# STM32U575 register map
File version: 1.4
CPU: CM33 r0p1, little endian, MPU, FPU, 4 interrupt priority bits
Registers are 32-bit, read-write, reset 0x0 unless marked. A register's access mark holds for its fields unless they carry their own. Offsets are from the block's base; [hi:lo] are bit positions; lines under a group give offsets from that group; {n}, {i} and the like mark numbered series; <NAME> marks a mode.

## LPDMA1
Base 0x46025000
Same registers: SEC_LPDMA1 0x56025000
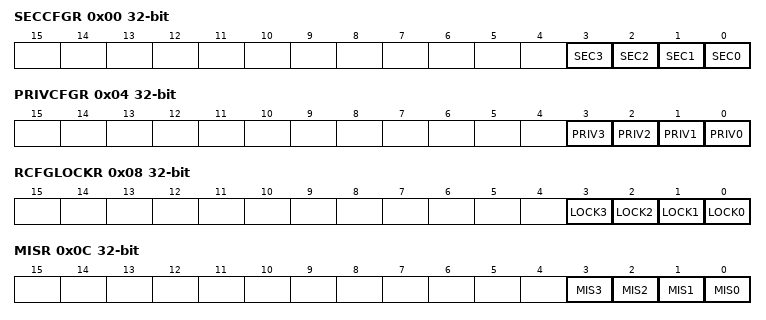
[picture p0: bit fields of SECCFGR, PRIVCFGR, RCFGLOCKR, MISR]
0x00 SECCFGR — LPDMA secure configuration register
  [n] SEC{n} (n=0..3) — SEC{n}
0x04 PRIVCFGR — LPDMA privileged configuration register
  [n] PRIV{n} (n=0..3) — PRIV{n}
0x08 RCFGLOCKR — LPDMA configuration lock register
  [n] LOCK{n} (n=0..3) — LOCK{n}
0x0C MISR ro — LPDMA non-secure masked interrupt status register
  [n] MIS{n} (n=0..3) — MIS{n}
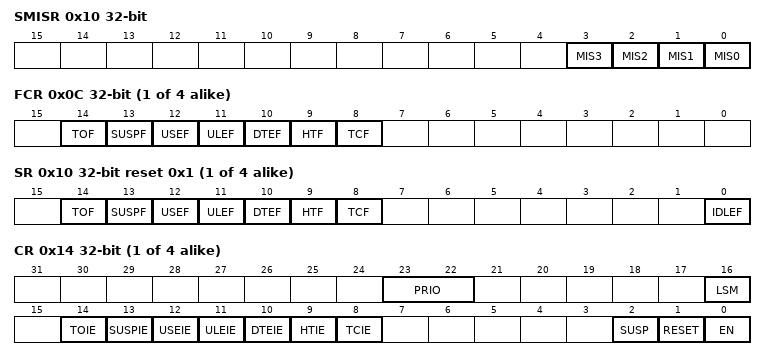
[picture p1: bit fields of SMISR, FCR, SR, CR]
0x10 SMISR ro — LPDMA secure masked interrupt status register
  [n] MIS{n} (n=0..3) — MIS{n}
{0x50+0x80*i} CH{i} (i=0..3) group — Cluster CH{i}, containing C?LBAR, C?FCR, C?SR, C?CR, C?TR1, C?TR2, C?BR1, C?SAR, C?DAR, C?LLR
  0x00 LBAR — LPDMA channel 0 linked-list base address register
    [31:16] LBA — linked-list base address of LPDMA channel x
  0x0C FCR wo — LPDMA channel 0 flag clear register
    [14] TOF — trigger overrun flag clear
    [13] SUSPF — completed suspension flag clear
    [12] USEF — user setting error flag clear
    [11] ULEF — update link transfer error flag clear
    [10] DTEF — data transfer error flag clear
    [9] HTF — half transfer flag clear
    [8] TCF — transfer complete flag clear
  0x10 SR ro reset 0x1 — LPDMA channel 0 status register
    [14] TOF — trigger overrun flag clear
    [13] SUSPF — completed suspension flag
    [12] USEF — user setting error flag
    [11] ULEF — update link transfer error flag
    [10] DTEF — data transfer error flag
    [9] HTF — half transfer flag An half transfer event is an half block transfer that occurs when half of the bytes of the source block size (rounded-up integer of LPDMA_CxBR1.BNDT[15:0] / 2) has been transferred to the destination.
    [8] TCF — transfer complete flag A transfer complete event is a block transfer complete or a LLI transfer complete including the upload of the next LLI if any, or the full linked-list completion, depending on the transfer complete event mode LPDMA_CxTR2.TCEM[1:0].
    [0] IDLEF — idle flag This idle flag is de-asserted by hardware when the channel is enabled (LPDMA_CxCR.EN = 1) with a valid channel configuration (no USEF to be immediately reported). This idle flag is asserted after hard reset or by hardware when the channel is back in idle state (in suspended or disabled state).
  0x14 CR access per field — LPDMA channel 0 control register
    [23:22] PRIO rw — priority level of the channel x LPDMA transfer versus others Note: This bit must be written when EN = 0. This bit is read-only when EN = 1.
    [16] LSM rw — Link step mode First the block transfer is executed as defined by the current internal register file until LPDMA_CxBR1.BNDT[15:0 ] =0). Secondly the next linked-list data structure is conditionally uploaded from memory as defined by LPDMA_CxLLR. Then channel execution is completed. Note: This bit must be written when EN=0. This bit is read-only when EN=1.
    [14] TOIE rw — trigger overrun interrupt enable
    [13] SUSPIE rw — completed suspension interrupt enable
    [12] USEIE rw — user setting error interrupt enable
    [11] ULEIE rw — update link transfer error interrupt enable
    [10] DTEIE rw — data transfer error interrupt enable
    [9] HTIE rw — half transfer complete interrupt enable
    [8] TCIE rw — transfer complete interrupt enable
    [2] SUSP rw — suspend Writing 1 into the field RESET (bit 1) causes the hardware to de-assert this bit, whatever is written into this bit 2. Else: Software must write 1 in order to suspend an active channel i.e. a channel with an on-going DMA transfer over its master ports. The software must write 0 in order to resume a suspended channel, following the programming sequence detailed in sequence.
    [1] RESET wo — reset This bit is write only. Writing 0 has no impact. Writing 1 implies the reset of the following: the channel internal state, SUSP and EN bits (whatever is written receptively in bit 2 and bit 0). The reset is effective when the channel is in steady state, meaning one of the following: - active channel in suspended state (LPDMA_CxSR.SUSPF = 1 and LPDMA_CxSR.IDLEF = LPDMA_CxCR.EN = 1) - channel in disabled state (LPDMA_CxSR.IDLEF = 1 and LPDMA_CxCR.EN = 0). After writing a RESET, to continue using this channel, the user must explicitly reconfigure the channel including the hardware-modified configuration registers (LPDMA_CxBR1, LPDMA_CxSAR and LPDMA_CxDAR) before enabling again the channel (see the programming sequence in ).
    [0] EN rw — enable Writing 1 into the field RESET (bit 1) causes the hardware to de-assert this bit, whatever is written into this bit 0. Else: this bit is de-asserted by hardware when there is a transfer error (master bus error or user setting error) or when there is a channel transfer complete (channel ready to be configured, e.g. if LSM=1 at the end of a single execution of the LLI). Else, this bit can be asserted by software. Writing 0 into this EN bit is ignored.
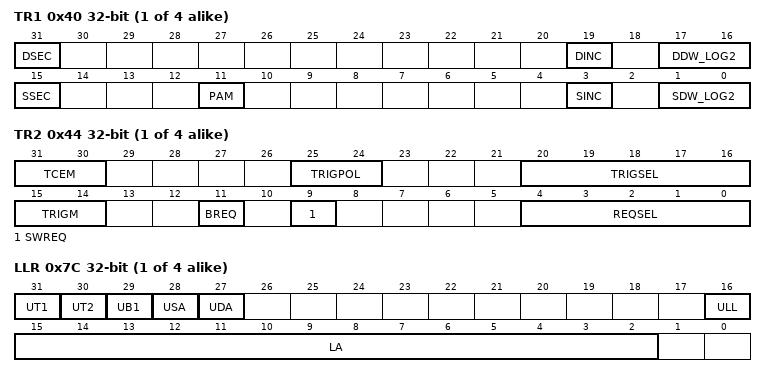
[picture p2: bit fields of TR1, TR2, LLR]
  0x40 TR1 — LPDMA channel 0 transfer register 1
    [31] DSEC — security attribute of the LPDMA transfer to the destination If LPDMA_SECCFGR.SECx = 1 and the access is secure: This is a secure register bit. This bit can only be read by a secure software. This bit must be written by a secure software when LPDMA_SECCFGR.SECx = 1. A secure write is ignored when LPDMA_SECCFGR.SECx = 0. When LPDMA_SECCFGR.SECx is de-asserted, this DSEC bit is also de-asserted by hardware (on a secure reconfiguration of the channel as non-secure), and the LPDMA transfer to the destination is non-secure.
    [19] DINC — destination incrementing single The destination address, pointed by LPDMA_CxDAR, is kept constant after a single transfer, or is incremented by the offset value corresponding to a contiguous data after a single transfer.
    [17:16] DDW_LOG2 — binary logarithm of the destination data width of a single in bytes Note: Setting a 8-byte data width causes a user setting error to be reported and none transfer is issued. A destination single transfer must have an aligned address with its data width (start address LPDMA_CxDAR[2:0] versus DDW_LOG2[1:0]). Otherwise a user setting error is reported and none transfer is issued.
    [15] SSEC — security attribute of the LPDMA transfer from the source If LPDMA_SECCFGR.SECx = 1 and the access is secure: This is a secure register bit. This bit can only be read by a secure software. This bit must be written by a secure software when LPDMA_SECCFGR.SECx =1 . A secure write is ignored when LPDMA_SECCFGR.SECx = 0. When LPDMA_SECCFGR.SECx is de-asserted, this SSEC bit is also de-asserted by hardware (on a secure reconfiguration of the channel as non-secure), and the LPDMA transfer from the source is non-secure.
    [11] PAM — padding/alignment mode If DDW_LOG2[1:0]=SDW_LOG2[1:0]: if the data width of a single destination transfer is equal to the data width of a single source transfer, this bit is ignored. Else: Case 1: If destination data width > source data width Case 2: If destination data width < source data width
    [3] SINC — source incrementing single The source address, pointed by LPDMA_CxSAR, is kept constant after a single transfer or is incremented by the offset value corresponding to a contiguous data after a single transfer.
    [1:0] SDW_LOG2 — binary logarithm of the source data width of a single in bytes Note: Setting a 8-byte data width causes a user setting error to be reported and none transfer is issued. a source block size must be a multiple of the source data width (LPDMA_CxBR1.BNDT[2:0] versus SDW_LOG2[1:0]). Otherwise, a user setting error is reported and no transfer is issued. A source single transfer must have an aligned address with its data width (start address LPDMA_CxSAR[2:0] versus SDW_LOG2[1:0]). Otherwise, a user setting error is reported and none transfer is issued.
  0x44 TR2 — LPDMA channel 0 transfer register 2
    [31:30] TCEM — transfer complete event mode These bits define the transfer granularity for the transfer complete and half transfer complete events generation. Note: If the initial LLI0 data transfer is null/void (directly programmed by the internal register file with LPDMA_CxBR1.BNDT[15:0] = 0), then neither the complete transfer event nor the half transfer event is generated. Note: If the initial LLI0 data transfer is null/void (i.e. directly programmed by the internal register file with LPDMA_CxBR1.BNDT[15:0] =0 ), then the half transfer event is not generated, and the transfer complete event is generated when is completed the loading of the LLI1.
    [25:24] TRIGPOL — trigger event polarity These bits define the polarity of the selected trigger event input defined by TRIGSEL[4:0].
    [20:16] TRIGSEL — trigger event input selection These bits select the trigger event input of the LPDMA transfer (as per Programmed LPDMA1 trigger), with an active trigger event if TRIGPOL[1:0] = 00.
    [15:14] TRIGM — trigger mode These bits define the transfer granularity for its conditioning by the trigger. If the channel x is enabled (LPDMA_CxCR.EN asserted) with TRIGPOL[1:0] = 0b00 or 0b11, these TRIGM[1:0] bits are ignored. Else, a DMA transfer is conditioned by at least one trigger hit: The LPDMA monitoring of a trigger for channel x is started when the channel is enabled/loaded with a new active trigger configuration: rising or falling edge on a selected trigger (TRIGPOL[1:0] = 0b01 or respectively TRIGPOL[1:0] = 0b10). The monitoring of this trigger is kept active during the triggered and uncompleted (data or link) transfer; and if a new trigger is detected then, this hit is internally memorized to grant the next transfer, as long as the defined rising or falling edge is not modified, and the TRIGSEL[4:0] is not modified, and the channel is enabled. Transferring a next LLIn+1 that updates the LPDMA_CxTR2 with a new value for any of TRIGSEL[4:0] or TRIGPOL[1:0], resets the monitoring, trashing the memorized hit of the formerly defined LLIn trigger. After a first new trigger hitn+1 is memorized, if another second trigger hitn+2 is detected and if the hitn triggered transfer is still not completed, hitn+2 is lost and not memorized, and a trigger overrun flag is reported (LPDMA_CxSR.TOF = 1), an interrupt is generated if enabled (LPDMA_CxCR.TOIE = 1). The channel is not automatically disabled by hardware due to a trigger overrun.
    [11] BREQ — block hardware request If the channel x is activated (LPDMA_CxCR.EN asserted) with SWREQ = 1 (software request for a memory-to-memory transfer), this bit is ignored. Else:
    [9] SWREQ — software request This bit is internally taken into account when LPDMA_CxCR.EN is asserted.
    [4:0] REQSEL — DMA hardware request selection These bits are ignored if channel x is activated (LPDMA_CxCR.EN asserted) with SWREQ = 1 (software request for a memory-to-memory transfer). Else, the selected hardware request is internally taken into account as per request. Note: The user must not assign a same input hardware request (same REQSEL[4:0] value) to different active DMA channels (LPDMA_CxCR.EN = 1 and LPDMA_CxTR2.SWREQ = 0 for these channels). DMA is not intended to hardware support the case of simultaneous enabled channels incorrectly configured with a same hardware peripheral request signal, and there is no user setting error reporting.
  0x48 BR1 — LPDMA channel 0 block register 1
    [15:0] BNDT — block number of data bytes to transfer from the source Block size transferred from the source. When the channel is enabled, this field becomes read-only and is decremented, indicating the remaining number of data items in the current source block to be transferred. BNDT[15:0] is programmed in number of bytes, maximum source block size is 64 Kbytes -1. Once the last data transfer is completed (BNDT[15:0] = 0): - if LPDMA_CxLLR.UB1 = 1, this field is updated by the LLI in the memory. - if LPDMA_CxLLR.UB1 = 0 and if there is at least one non null Uxx update bit, this field is internally restored to the programmed value. - if all LPDMA_CxLLR.Uxx = 0 and if LPDMA_CxLLR.LA[15:0] = 0, this field is internally restored to the programmed value (infinite/continuous last LLI). - if LPDMA_CxLLR = 0, this field is kept as zero following the last LLI data transfer. Note: A non-null source block size must be a multiple of the source data width (BNDT[2:0] versus LPDMA_CxTR1.SDW_LOG2[1:0]). Else a user setting error is reported and none transfer is issued.
  0x4C SAR — LPDMA channel 0 source address register
    [31:0] SA — source address This field is the pointer to the address from which the next data is read. During the channel activity, depending on the source addressing mode (LPDMA_CxTR1.SINC), this field is either kept fixed or incremented by the data width (LPDMA_CxTR1.SDW_LOG2[1:0]) after each single source data, reflecting the next address from which data is read. In linked-list mode, after a LLI data transfer is completed, this register is automatically updated by LPDMA from the memory, provided the LLI is set with LPDMA_CxLLR.USA = 1. Note: A source address must be aligned with the programmed data width of a source single (SA[32:0] versus LPDMA_CxTR1.SDW_LOG2[1:0]). Else, a user setting error is reported and no transfer is issued.
  0x50 DAR — LPDMA channel 0 destination address register
    [31:0] DA — destination address This field is the pointer to the address from which the next data is written. During the channel activity, depending on the destination addressing mode (LPDMA_CxTR1.DINC), this field is kept fixed or incremented by the data width (LPDMA_CxTR1.DDW_LOG2[21:0]) after each single destination data, reflecting the next address from which data is written. In linked-list mode, after a LLI data transfer is completed, this register is automatically updated by DMA from the memory, provided the LLI is set with LPDMA_CxLLR.UDA = 1. Note: A destination address must be aligned with the programmed data width of a destination single (DA[2:0] versus LPDMA_CxTR1.DDW_LOG2[1:0]). Else, a user setting error is reported and no transfer is issued.
  0x7C LLR — LPDMA channel 0 linked-list address register
    [31] UT1 — Update LPDMA_CxTR1 from memory This bit controls the update of the LPDMA_CxTR1 register from the memory during the link transfer.
    [30] UT2 — Update LPDMA_CxTR2 from memory This bit controls the update of the LPDMA_CxTR2 register from the memory during the link transfer.
    [29] UB1 — Update LPDMA_CxBR1 from memory This bit controls the update of the LPDMA_CxBR1 register from the memory during the link transfer.
    [28] USA — update LPDMA_CxSAR from memory This bit controls the update of the LPDMA_CxSAR register from the memory during the link transfer.
    [27] UDA — Update LPDMA_CxDAR register from memory This bit is used to control the update of the LPDMA_CxDAR register from the memory during the link transfer.
    [16] ULL — Update LPDMA_CxLLR register from memory This bit is used to control the update of the LPDMA_CxLLR register from the memory during the link transfer.
    [15:2] LA — pointer (16-bit low-significant address) to the next linked-list data structure If UT1 = UT2 = UB1 = USA = UDA = ULL = 0 and if LA[15:20] = 0, the current LLI is the last one. The channel transfer is completed without any update of the linked-list DMA register file. Else, this field is the pointer to the memory address offset from which the next linked-list data structure is automatically fetched from, once the data transfer is completed, in order to conditionally update the linked-list DMA internal register file (LPDMA_CxCTR1, LPDMA_CxTR2, LPDMA_CxBR1, LPDMA_CxSAR, LPDMA_CxDAR and LPDMA_CxLLR). Note: The user must program the pointer to be 32-bit aligned. The two low-significant bits are write ignored.
